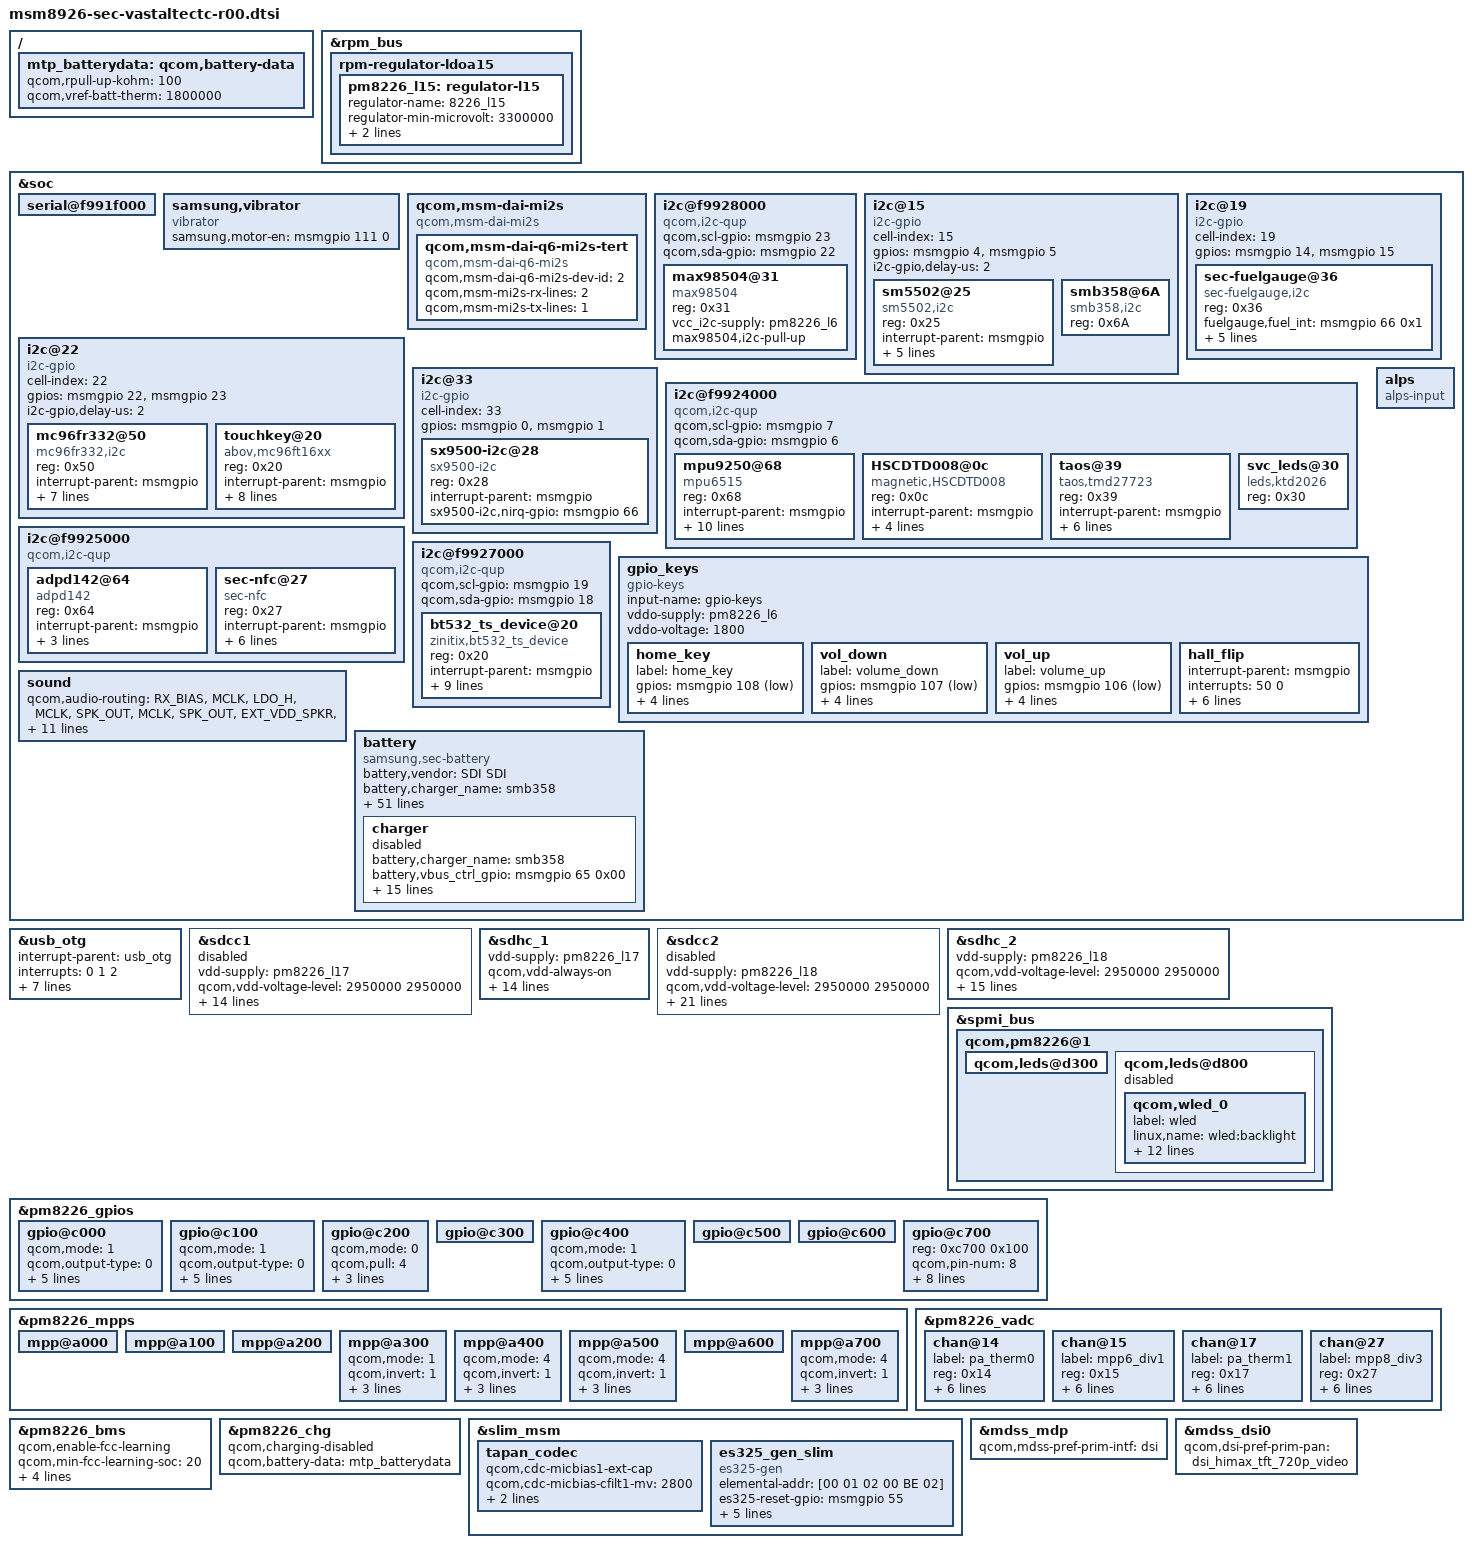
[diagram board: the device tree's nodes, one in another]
/* Copyright (c) 2013, The Linux Foundation. All rights reserved.
 *
 * This program is free software; you can redistribute it and/or modify
 * it under the terms of the GNU General Public License version 2 and
 * only version 2 as published by the Free Software Foundation.
 *
 * This program is distributed in the hope that it will be useful,
 * but WITHOUT ANY WARRANTY; without even the implied warranty of
 * MERCHANTABILITY or FITNESS FOR A PARTICULAR PURPOSE.  See the
 * GNU General Public License for more details.
 */

/include/ "msm8926-camera-sensor-mtp-vastaltectc-r00.dtsi"
/*/include/ "dsi_panel_magna_octa_720p_video_revA.dtsi"*/
/include/ "dsi_panel_himax_hx8394c_tft_720p_video.dtsi"
&rpm_bus {
	rpm-regulator-ldoa15 {
		status = "okay";
		pm8226_l15: regulator-l15 {
			regulator-name = "8226_l15";
			regulator-min-microvolt = <3300000>;
			regulator-max-microvolt = <3300000>;
			qcom,init-voltage = <3300000>;
			status = "okay";
		};
	};
};

&soc {
	serial@f991f000 {
		status = "ok";
	};

	samsung,vibrator{
		compatible = "vibrator";
		samsung,motor-en = <&msmgpio 111 0>;
		status = "ok";
	};

	 /*CONFIG_SND_SOC_MAX98504*/
	qcom,msm-dai-mi2s {
			compatible = "qcom,msm-dai-mi2s";
			qcom,msm-dai-q6-mi2s-tert {
			compatible = "qcom,msm-dai-q6-mi2s";
			qcom,msm-dai-q6-mi2s-dev-id = <2>;
			qcom,msm-mi2s-rx-lines = <2>;
			qcom,msm-mi2s-tx-lines = <1>;
		};
	};

	i2c@f9928000 {	 /*BLSP-1 QUP-6*/
		compatible = "qcom,i2c-qup";
		qcom,scl-gpio = <&msmgpio 23 0>;
		qcom,sda-gpio = <&msmgpio 22 0>;
		max98504@31 {
			compatible = "max98504";
			reg = <0x31>;
			vcc_i2c-supply = <&pm8226_l6>;
			max98504,i2c-pull-up;
		};
	};	/*CONFIG_SND_SOC_MAX98504*/


	i2c@15{ /*SM5502 MUIC Chip node */
		/*Driver file: drivers/misc/sm5502.c*/
		/*CONFIG_SM5502_MUIC*/
                cell-index = <15>;
                compatible = "i2c-gpio";
                gpios = <&msmgpio 4 0  /*SDA*/
                        &msmgpio 5 0  /*SCL*/
                        >;
                i2c-gpio,delay-us = <2>;
                #address-cells = <1>;
                #size-cells = <0>;
                sm5502@25{
                        compatible = "sm5502,i2c";
                        reg = <0x25>;
                        interrupt-parent = <&msmgpio>;
                        interrupts= <52 0>;
                        sm5502,irq-gpio = <&msmgpio 52 0x00>;
                        sm5502,gpio-sda = <&msmgpio 4 0x00>;
                        sm5502,gpio-scl = <&msmgpio 5 0x00>;
                        sm5502,uarton-gpio = <&msmgpio 109 0x00>;
                };
                smb358@6A {
						compatible = "smb358,i2c";
						reg = <0x6A>;
				};
        };

	i2c@19 {
		cell-index = <19>;
		compatible = "i2c-gpio";
		gpios = <&msmgpio 14 0  /* sda */
			&msmgpio 15 0   /* scl */
			>;
		#address-cells = <1>;
		#size-cells = <0>;
		sec-fuelgauge@36 {
			compatible = "sec-fuelgauge,i2c";
			reg = <0x36>;
			fuelgauge,fuel_int = <&msmgpio 66 0x1>;
			fuelgauge,capacity_max = <1000>;
			fuelgauge,capacity_max_margin = <50>;
			fuelgauge,capacity_min = <0>;
			fuelgauge,capacity_calculation_type = <0x17>;
			fuelgauge,fuel_alert_soc = <1>;
			/* fuelgaguge,repeated_fuelalert; */
		};
       };

	i2c@22 { /*MC96FR332/MC96FR116 IRDA Controller IC node*/
		 /*Drvier file: drivers/irda/ir_remote_kmini.c*/
		 /*CONFIG_IR_REMOCON_KMINI*/
		cell-index = <22>;
                compatible = "i2c-gpio";
                gpios = <&msmgpio 22 0 /* sda */
                         &msmgpio 23 0 /* scl */
                         >;
                i2c-gpio,delay-us = <2>;
                #address-cells = <1>;
                #size-cells = <0>;

		mc96fr332@50 {
			compatible = "mc96fr332,i2c";
                        reg = <0x50>;
                        interrupt-parent = <&msmgpio>;
                        vled_3.3v-supply = <&pm8226_l15>;
                        interrupts = <56 0>;
			mc96fr332,irda_irq_gpio = <&msmgpio 56 0x00>;
                        mc96fr332,irda_wake = <&msmgpio 49 0x00>;
			mc96fr332,irda_poweron = <&msmgpio 114 0x00>;
			mc96fr332,scl-gpio = <&msmgpio 23 0x00>;
			mc96fr332,sda-gpio = <&msmgpio 22 0x00>;
		};

		touchkey@20{
			compatible = "abov,mc96ft16xx";
			reg = <0x20>;
			interrupt-parent = <&msmgpio>;
			interrupts = <31 0>;
			abov,sda-gpio = <&msmgpio 22 0>;
			abov,scl-gpio = <&msmgpio 23 0>;
			abov,irq-gpio = <&msmgpio 31 0>;
			abov,rst-gpio = <&msmgpio 38 0>;
			abov,tkey_en-gpio = <&msmgpio 110 0>;
			vddo-supply = <&pm8226_l6>;
			avdd-supply = <&pm8226_l19>;
		};
	};

	i2c@33{
		cell-index = <33>;
		compatible = "i2c-gpio";
		gpios = <&msmgpio 0 0
			&msmgpio 1 0>;
	sx9500-i2c@28 {
			compatible = "sx9500-i2c";
			reg = <0x28>;
			interrupt-parent = <&msmgpio>;
			sx9500-i2c,nirq-gpio = <&msmgpio 66 0x00>;
		};
	};

	i2c@f9924000 { /* BLSP1 QUP2 */
		compatible = "qcom,i2c-qup";
		qcom,scl-gpio = <&msmgpio 7 0>;
		qcom,sda-gpio = <&msmgpio 6 0>;
		status = "okay";
		mpu9250@68 {
			compatible = "mpu6515";
			reg = <0x68>;
			interrupt-parent = <&msmgpio>;
			mpu9250,device_rev = <0>;
			mpu9250,irq_gpio = <&msmgpio 64 0x0>;
			mpu9250,int_config = <0>;
			mpu9250,level_shifter = <0>;
			mpu9250,sec_slave_type = <0>;
			mpu9250,sec_slave_id = <0>;
			mpu9250,orientation = <2 1 1 1 2 1 1 1 2>;
			mpu9250,key = <211 22 205 7
				217 186 151 55
				206 254 35 144
				225 102 47 50>;
			mpu9250-lvs1-supply = <&pm8226_lvs1>;
		};

		HSCDTD008@0c {
			compatible = "magnetic,HSCDTD008";
			reg = <0x0c>;
			interrupt-parent = <&msmgpio>;
			interrupts = <66 0>;
			HSCDTD008-i2c,irq_gpio = <&msmgpio 66 0x1>;
			HSCDTD008-i2c,reg_vdd = "8226_l19";
			HSCDTD008-i2c,reg_vio = "8226_lvs1";
		};

		taos@39 {
			compatible = "taos,tmd27723";
			reg = <0x39>;
			interrupt-parent = <&msmgpio>;
			interrupts = <65 0>;
			taos,irq_gpio = <&msmgpio 65 0>;
			taos,en = <&pm8226_gpios 2 0x00>;
			taos,prox_cal_path = "/efs/prox_cal";
			taos,vdd_2p85 = "8226_l19";
			taos,vdd_1p8 = "8226_lvs1";
		};

		svc_leds@30{
			compatible = "leds,ktd2026";
			reg = <0x30>;
		};
	};
	i2c@f9925000 {
		compatible = "qcom,i2c-qup";
		status = "okay";
		adpd142@64 {
			compatible = "adpd142";
			reg = <0x64>;
			interrupt-parent = <&msmgpio>;
			interrupts = <63 0>;
			adpd142,irq_gpio = <&msmgpio 63 0>;
			adpd142,vdd_1p8 = "8226_l6";
		};
		sec-nfc@27 {
			compatible = "sec-nfc";
			reg = <0x27>;
			interrupt-parent = <&msmgpio>;
			interrupts = <21 0>;
			vdd_nfc-supply = <&pm8226_l6>;
			sec-nfc,firm-gpio = <&msmgpio 62 0x00>;
			sec-nfc,ven-gpio = <&msmgpio 20 0x00>;
			sec-nfc,irq-gpio = <&msmgpio 21 0x01>;
			nfc_ldo-supply = <&pm8226_l22>;
		};
	};

	i2c@f9927000{ /* BLSP1 QUP5 Hardware ID BLSP5 */
		compatible = "qcom,i2c-qup";
		qcom,scl-gpio = <&msmgpio 19 0>;
		qcom,sda-gpio = <&msmgpio 18 0>;
		bt532_ts_device@20 {
				compatible = "zinitix,bt532_ts_device";
				reg = <0x20>;
				interrupt-parent = <&msmgpio>;
				interrupts = <17 0>;
				zinitix,vdd_en-gpio = <&msmgpio 31 0x00>;
				zinitix,irq-gpio = <&msmgpio 17 0x00>;
				zinitix,x_resolution = <720>;
				zinitix,y_resolution = <1280>;
				zinitix,page_size = <128>;
				zinitix,orientation = <0>;
				vddo-supply = <&pm8226_lvs1>;
				zinitix,tsp_vdd_supply_type = <0>;
			};
	};

	gpio_keys {
		compatible = "gpio-keys";
		input-name = "gpio-keys";
		vddo-supply = <&pm8226_l6>;
		vddo-voltage = <1800>;


		home_key {
			label = "home_key";
			gpios = <&msmgpio 108 0x1>;
			linux,input-type = <1>;
			linux,code = <172>;
			gpio-key,wakeup;
			debounce-interval = <15>;
		};

		vol_down {
			label = "volume_down";
			gpios = <&msmgpio 107 0x1>;
			linux,input-type = <1>;
			linux,code = <114>;
			gpio-key,wakeup;
			debounce-interval = <15>;
		};

		vol_up {
			label = "volume_up";
			gpios = <&msmgpio 106 0x1>;
			linux,input-type = <1>;
			linux,code = <115>;
			gpio-key,wakeup;
			debounce-interval = <15>;
		};

		hall_flip {
			interrupt-parent = <&msmgpio>;
			interrupts = <50 0>;

			label = "hall_flip";
			gpios = <&msmgpio 50 0>;
			linux,input-type = <1>;
			linux,code = <0x15>;
			gpio-key,wakeup;
			debounce-interval = <15>;
		};
	};

	alps {
			compatible = "alps-input";
	};

	sound {
		qcom,audio-routing =
			"RX_BIAS", "MCLK",
			"LDO_H", "MCLK",
			"SPK_OUT", "MCLK",
			"SPK_OUT", "EXT_VDD_SPKR",
			"AMIC1", "MIC BIAS1 External",
			"MIC BIAS1 External", "Handset Mic",
			"AMIC2", "MIC BIAS2 External",
			"MIC BIAS2 External", "Headset Mic",
			"AMIC3", "MIC BIAS3 External",
			"MIC BIAS3 External", "Sub Mic",
			"AMIC4", "MIC BIAS2 External",
			"MIC BIAS2 External", "ANCRight Headset Mic",
			"AMIC5", "MIC BIAS2 External",
			"MIC BIAS2 External", "ANCLeft Headset Mic";

		qcom,cdc-mclk-gpios = <&pm8226_gpios 1 0>;
		/*qcom,cdc-vdd-spkr-gpios = <&pm8226_gpios 2 0>;*/
		vdd-earjack-supply = <&pm8226_l19>;
	};

	battery {
		status = "okay";
		compatible = "samsung,sec-battery";
		battery,vendor = "SDI SDI";
		battery,charger_name = "smb358";
		battery,fuelgauge_name = "bms";
		battery,technology = <2>; /* POWER_SUPPLY_TECHNOLOGY_LION */

		battery,chip_vendor = "QCOM";
		battery,temp_adc_type = <1>; /* SEC_BATTERY_ADC_TYPE_AP */

		battery,polling_time = <10 30 30 30 3600>;

		battery,adc_check_count = <5>;

		battery,cable_check_type = <5>; /* SEC_BATTERY_CABLE_CHECK_PSY */
		battery,cable_source_type = <1>; /* SEC_BATTERY_CABLE_SOURCE_EXTERNAL */
		battery,event_check;
		battery,event_waiting_time = <600>;
		battery,polling_type = <1>; /* SEC_BATTERY_MONITOR_ALARM */
		battery,monitor_initial_count = <3>;

		battery,battery_check_type = <0>; /* SEC_BATTERY_CHECK_NONE */
		battery,check_count = <0>;
		battery,check_adc_max = <1440>;
		battery,check_adc_min = <0>;

		battery,ovp_uvlo_check_type = <3>; /* SEC_BATTERY_OVP_UVLO_CHGPOLLING */

		battery,thermal_source = <2>; /* SEC_BATTERY_THERMAL_SOURCE_ADC */

		battery,temp_table_adc = <27281 27669 28178 28724 29342 30101 30912 31807 32823 33858 34950 36049 37054
			38025 38219 38448 38626 38795 38989 39229 39540 39687 39822 40523 41123 41619>;
		battery,temp_table_data = <700 650 600 550 500 450 400 350 300 250 200 150 100
			50 40 30 20 10 0 (-10) (-30) (-40) (-50) (-100) (-150) (-200)>;
		battery,temp_check_type = <2>; /* SEC_BATTERY_TEMP_CHECK_TEMP */
		battery,temp_check_count = <1>;
		battery,temp_high_threshold_event = <600>;
		battery,temp_high_recovery_event = <450>;
		battery,temp_low_threshold_event = <(-50)>;
		battery,temp_low_recovery_event = <0>;
		battery,temp_high_threshold_normal = <600>;
		battery,temp_high_recovery_normal = <450>;
		battery,temp_low_threshold_normal = <(-50)>;
		battery,temp_low_recovery_normal = <0>;
		battery,temp_high_threshold_lpm = <600>;
		battery,temp_high_recovery_lpm = <450>;
		battery,temp_low_threshold_lpm = <(-50)>;
		battery,temp_low_recovery_lpm = <0>;
		battery,full_check_type = <2>; /* SEC_BATTERY_FULLCHARGED_FG_CURRENT */
		battery,full_check_type_2nd = <3>; /* SEC_BATTERY_FULLCHARGED_TIME */
		battery,full_check_count = <1>;
		battery,chg_gpio_full_check = <0>;
		battery,chg_polarity_full_check = <1>;

		/* SEC_BATTERY_FULL_CONDITION_SOC |
		   SEC_BATTERY_FULL_CONDITION_NOTIMEFULL |
		   SEC_BATTERY_FULL_CONDITION_VCELL */
		battery,full_condition_type = <13>;
		battery,full_condition_soc = <97>;
		battery,full_condition_vcell = <4300>;

		battery,recharge_check_count = <1>;
		battery,recharge_condition_type = <4>; /* SEC_BATTERY_RECHARGE_CONDITION_VCELL */
		battery,recharge_condition_soc = <98>;
		battery,recharge_condition_vcell = <4300>;

		battery,charging_total_time = <36000>;
		battery,recharging_total_time = <5400>;
		battery,charging_reset_time = <0>;

		charger{
			status = "disable";
			/* Charger */
			battery,charger_name = "smb358";
			battery,vbus_ctrl_gpio = <&msmgpio 65 0x00>;
			battery,chg_gpio_en = <0>;
			battery,chg_polarity_en = <0>;
			battery,chg_gpio_status = <0>;
			battery,chg_polarity_status = <0>;
			battery,chg_float_voltage = <4340>;
			battery,ovp_uvlo_check_type = <3>; /* SEC_BATTERY_OVP_UVLO_CHGPOLLING */
			battery,full_check_type = <2>; /* SEC_BATTERY_FULLCHARGED_FG_CURRENT */

			battery,input_current_limit = <1000 460 460 1000 460 900 1000 460 460 1000 650 1000 1000 460 1300 300 700 1300 300 1000 1000 460 460>;
			battery,fast_charging_current = <2100 0 460 2100 460 1200 1000 460 0 1200 750 2100 2100 0 1300 300 700 1300 300 1000 2100 0 0>;
			battery,full_check_current_1st = <250 0 250 250 250 250 250 250 0 250 250 250 250 0 250 250 250 250 250 250 250 0 0>;
			battery,full_check_current_2nd = <2400 0 2400 2400 2400 2400 2400 2400 0 2400 2400 2400 2400 0 2400 2400 2400 2400 2400 2400 2400 0 0>;
		};
	};
};

&usb_otg {
	#address-cells = <0>;
	interrupt-parent = <&usb_otg>;
	interrupts = <0 1 2>;
	#interrupt-cells = <1>;
	interrupt-map-mask = <0xffffffff>;
	interrupt-map = <0 &intc 0 134 0
			1 &intc 0 140 0
			2 &spmi_bus 0x0 0x0 0x9 0x0>;
	interrupt-names = "core_irq", "async_irq", "pmic_id_irq";

	qcom,hsusb-otg-mode = <3>;
	vbus_otg-supply = <&pm8226_chg_otg>;
	qcom,hsusb-otg-phy-init-seq =
			<0x44 0x80 0x6F 0x81 0x24 0x82 0x13 0x83 0xffffffff>;
};

&sdcc1 {
	vdd-supply = <&pm8226_l17>;
	qcom,vdd-voltage-level = <2950000 2950000>;
	qcom,vdd-current-level = <800 500000>;

	vdd-io-supply = <&pm8226_l6>;
	qcom,vdd-io-always-on;
	qcom,vdd-io-voltage-level = <1800000 1800000>;
	qcom,vdd-io-current-level = <250 154000>;

	qcom,pad-pull-on = <0x0 0x3 0x3>; /* no-pull, pull-up, pull-up */
	qcom,pad-pull-off = <0x0 0x3 0x3>; /* no-pull, pull-up, pull-up */
	qcom,pad-drv-on = <0x4 0x4 0x4>; /* 10mA, 10mA, 10mA */
	qcom,pad-drv-off = <0x0 0x0 0x0>; /* 2mA, 2mA, 2mA */

	qcom,clk-rates = <400000 25000000 50000000 100000000 200000000>;
	qcom,sup-voltages = <2950 2950>;

	qcom,bus-speed-mode = "HS200_1p8v", "DDR_1p8v";
	qcom,nonremovable;

	status = "disabled";
};

&sdhc_1 {
	vdd-supply = <&pm8226_l17>;
	qcom,vdd-always-on;
	qcom,vdd-voltage-level = <2950000 2950000>;
	qcom,vdd-current-level = <800 500000>;

	vdd-io-supply = <&pm8226_l6>;
	qcom,vdd-io-always-on;
	qcom,vdd-io-voltage-level = <1800000 1800000>;
	qcom,vdd-io-current-level = <250 154000>;

	qcom,pad-pull-on = <0x0 0x3 0x3>; /* no-pull, pull-up, pull-up */
	qcom,pad-pull-off = <0x0 0x3 0x3>; /* no-pull, pull-up, pull-up */
	qcom,pad-drv-on = <0x4 0x4 0x4>; /* 10mA, 10mA, 10mA */
	qcom,pad-drv-off = <0x0 0x0 0x0>; /* 2mA, 2mA, 2mA */

	qcom,clk-rates = <400000 25000000 50000000 100000000 200000000>;
	qcom,bus-speed-mode = "HS200_1p8v", "DDR_1p8v";
	qcom,nonremovable;

	status = "ok";
};

&sdcc2 {
	vdd-supply = <&pm8226_l18>;
	qcom,vdd-voltage-level = <2950000 2950000>;
	qcom,vdd-current-level = <9000 800000>;

	vdd-io-supply = <&pm8226_l21>;
	qcom,vdd-io-voltage-level = <1800000 2950000>;
	qcom,vdd-io-current-level = <6 22000>;

	qcom,pad-pull-on = <0x0 0x3 0x3>; /* no-pull, pull-up, pull-up */
	qcom,pad-pull-off = <0x0 0x3 0x3>; /* no-pull, pull-up, pull-up */
	qcom,pad-drv-on = <0x4 0x4 0x4>; /* 10mA, 10mA, 10mA */
	qcom,pad-drv-off = <0x0 0x0 0x0>; /* 2mA, 2mA, 2mA */

	qcom,clk-rates = <400000 25000000 50000000 100000000 200000000>;
	qcom,sup-voltages = <2950 2950>;

	qcom,xpc;
	qcom,bus-speed-mode = "SDR12", "SDR25", "SDR50", "DDR50", "SDR104";
	qcom,current-limit = <600>; #address-cells = <0>; interrupt-parent = <&sdcc2>;
	interrupts = <0 1 2>;
	#interrupt-cells = <1>;
	interrupt-map-mask = <0xffffffff>;
	interrupt-map = <0 &intc 0 125 0
			1 &intc 0 220 0
			2 &msmgpio 38 0x3>;
	interrupt-names = "core_irq", "bam_irq", "status_irq";
	cd-gpios = <&msmgpio 38 0x1>;

	status = "disabled";
};

&sdhc_2 {
	vdd-supply = <&pm8226_l18>;
	qcom,vdd-voltage-level = <2950000 2950000>;
	qcom,vdd-current-level = <9000 800000>;

	vdd-io-supply = <&pm8226_l21>;
	qcom,vdd-io-voltage-level = <1800000 2950000>;
	qcom,vdd-io-current-level = <6 22000>;

	qcom,pad-pull-on = <0x0 0x3 0x3>; /* no-pull, pull-up, pull-up */
	qcom,pad-pull-off = <0x0 0x3 0x3>; /* no-pull, pull-up, pull-up */
	qcom,pad-drv-on = <0x4 0x4 0x4>; /* 10mA, 10mA, 10mA */
	qcom,pad-drv-off = <0x0 0x0 0x0>; /* 2mA, 2mA, 2mA */

	qcom,clk-rates = <400000 25000000 50000000 100000000 200000000>;

	#address-cells = <0>;
	interrupt-parent = <&sdhc_2>;
	interrupts = <0 1 2>;
	#interrupt-cells = <1>;
	interrupt-map-mask = <0xffffffff>;
	interrupt-map = <0 &intc 0 125 0
			1 &intc 0 221 0
			2 &msmgpio 38 0x3>;
	interrupt-names = "hc_irq", "pwr_irq", "status_irq";

	status = "ok";
};

&spmi_bus {
	qcom,pm8226@1 {
                qcom,leds@d300 {
                        status = "okay";
                };

		qcom,leds@d800 {
			status = "disabled"; /*If WLED is not used for Backlight control*/
			qcom,wled_0 {		/*for TFT Panel, this to be disabled */
				label = "wled";
				linux,name = "wled:backlight";
				linux,default-trigger = "bkl-trigger";
				qcom,cs-out-en;
				qcom,op-fdbck = <1>;
				qcom,default-state = "off";
				qcom,max-current = <20>;
				qcom,ctrl-delay-us = <0>;
				qcom,boost-curr-lim = <3>;
				qcom,cp-sel = <0>;
				qcom,switch-freq = <11>;
				qcom,ovp-val = <0>;
				qcom,num-strings = <1>;
				qcom,id = <0>;
			};
		};
	};
};

&pm8226_gpios {
	gpio@c000 { /* GPIO 1 */
		/* XO_PMIC_CDC_MCLK enable for tapan codec */
		qcom,mode = <1>;		/* Digital output */
		qcom,output-type = <0>;	/* CMOS logic */
		qcom,pull = <5>;		/* QPNP_PIN_PULL_NO*/
		qcom,vin-sel = <3>;		/* QPNP_PIN_VIN3 */
		qcom,out-strength = <3>;/* QPNP_PIN_OUT_STRENGTH_HIGH */
		qcom,src-sel = <2>;		/* QPNP_PIN_SEL_FUNC_1 */
		qcom,master-en = <1>;	/* Enable GPIO */
	};

	gpio@c100 { /* GPIO 2 */
		qcom,mode = <1>;
		qcom,output-type = <0>;
		qcom,pull = <5>;
		qcom,vin-sel = <3>;
		qcom,out-strength = <3>;
		qcom,src-sel = <2>;
		qcom,master-en = <1>;
	};

	gpio@c200 { /* GPIO 3 */
		qcom,mode = <0>;
		qcom,pull = <4>;
		qcom,vin-sel = <2>;
		qcom,src-sel = <0>;
		qcom,master-en = <1>;
	};

	gpio@c300 { /* GPIO 4 */
	};

	gpio@c400 { /* GPIO 5 */
		qcom,mode = <1>;		/* Digital output */
		qcom,output-type = <0>;	/* CMOS logic */
		qcom,pull = <5>;		/* QPNP_PIN_PULL_NO */
		qcom,vin-sel = <3>;		/* QPNP_PIN_VIN2 */
		qcom,out-strength = <3>;/* QPNP_PIN_OUT_STRENGTH_HIGH */
		qcom,src-sel = <2>;		/* QPNP_PIN_SEL_FUNC_1 */
		qcom,master-en = <1>;
	};

	gpio@c500 { /* GPIO 6 */
	};

	gpio@c600 { /* GPIO 7 */
	};

	gpio@c700 { /* GPIO 8 */
		reg = <0xc700 0x100>;
		qcom,pin-num = <8>;
		qcom,mode = <1>;		/* QPNP_PIN_MODE_DIG_OUT */
		qcom,output-type = <0>;		/* QPNP_PIN_OUT_BUF_CMOS */
		qcom,invert = <0>;		/* QPNP_PIN_INVERT_DISABLE */
		qcom,pull = <5>;		/* QPNP_PIN_PULL_NO */
		qcom,vin-sel = <2>;		/* QPNP_PIN_VIN2 = S3 = 1.8V */
		qcom,out-strength = <2>;	/* QPNP_PIN_OUT_STRENGTH_MED */
		qcom,src-sel = <0>;		/* QPNP_PIN_SEL_FUNC_CONSTANT */
		qcom,master-en = <1>;		/* enable this gpio */
	};
};

&pm8226_mpps {
	mpp@a000 { /* MPP 1 */
	};

	mpp@a100 { /* MPP 2 */
	};

	mpp@a200 { /* MPP 3 */
	};

	mpp@a300 { /* MPP 4 */
		qcom,mode = <1>; /*QPNP_PIN_MODE_DIG_OUT */
		qcom,invert = <1>; /* Enable MPP */
		qcom,out-strength = <3>; /*QPNP_PIN_OUT_STRENGTH_HIGH*/
		qcom,master-en = <1>;
		qcom,src-sel = <0>; /* Function constant */
	};

	mpp@a400 { /* MPP 5 */
		/* PA_THERM0 config */
		qcom,mode = <4>; /* AIN input */
		qcom,invert = <1>; /* Enable MPP */
		qcom,ain-route = <0>; /* AMUX 5 */
		qcom,master-en = <1>;
		qcom,src-sel = <0>; /* Function constant */
	};

	mpp@a500 { /* MPP 6 */
		qcom,mode = <4>; /* AIN input */
		qcom,invert = <1>; /* Enable MPP */
		qcom,ain-route = <1>; /* AMUX 6 */
		qcom,master-en = <1>;
		qcom,src-sel = <0>; /* Function constant */
	};

	mpp@a600 { /* MPP 7 */
	};

	mpp@a700 { /* MPP 8 */
		/* PA_THERM1 config */
		qcom,mode = <4>; /* AIN input */
		qcom,invert = <1>; /* Enable MPP */
		qcom,ain-route = <3>; /* AMUX 8 */
		qcom,master-en = <1>;
		qcom,src-sel = <0>; /* Function constant */
	};
};

&pm8226_vadc {
	chan@14 {
		label = "pa_therm0";
		reg = <0x14>;
		qcom,decimation = <0>;
		qcom,pre-div-channel-scaling = <0>;
		qcom,calibration-type = "ratiometric";
		qcom,scale-function = <2>;
		qcom,hw-settle-time = <2>;
		qcom,fast-avg-setup = <0>;
	};

	chan@15 {
		label = "mpp6_div1";
		reg = <0x15>;
		qcom,decimation = <0>;
		qcom,pre-div-channel-scaling = <0>;
		qcom,calibration-type = "absolute";
		qcom,scale-function = <0>;
		qcom,hw-settle-time = <0>;
		qcom,fast-avg-setup = <0>;
	};
	chan@17 {
		label = "pa_therm1";
		reg = <0x17>;
		qcom,decimation = <0>;
		qcom,pre-div-channel-scaling = <0>;
		qcom,calibration-type = "ratiometric";
		qcom,scale-function = <2>;
		qcom,hw-settle-time = <2>;
		qcom,fast-avg-setup = <0>;
	};

	chan@27 {
		label = "mpp8_div3";
		reg = <0x27>;
		qcom,decimation = <0>;
		qcom,pre-div-channel-scaling = <1>;
		qcom,calibration-type = "absolute";
		qcom,scale-function = <0>;
		qcom,hw-settle-time = <0>;
		qcom,fast-avg-setup = <0>;
		};
};

/ {
	mtp_batterydata: qcom,battery-data {
		qcom,rpull-up-kohm = <100>;
		qcom,vref-batt-therm = <1800000>;

		/include/ "batterydata-palladium.dtsi"
		/include/ "batterydata-mtp-3000mah.dtsi"
	};
};

&pm8226_bms {
	status = "ok";
	qcom,enable-fcc-learning;
	qcom,min-fcc-learning-soc = <20>;
	qcom,min-fcc-ocv-pc = <30>;
	qcom,min-fcc-learning-samples = <5>;
	qcom,fcc-resolution = <10>;
	qcom,battery-data = <&mtp_batterydata>;
};

&pm8226_chg {
	qcom,charging-disabled;
	qcom,battery-data = <&mtp_batterydata>;
};

&slim_msm {
	tapan_codec {
		qcom,cdc-micbias1-ext-cap;
		qcom,cdc-micbias-cfilt1-mv = <2800>;
		qcom,cdc-micbias-cfilt2-mv = <2800>;
		qcom,cdc-micbias-cfilt3-mv = <2800>;
	};
	es325_gen_slim {
                compatible = "es325-gen";
                elemental-addr = [00 01 02 00 BE 02];

                es325-reset-gpio = <&msmgpio 55 0>;
                es325-wakeup-gpio = <&msmgpio 53 0>;
                vdd-2mic-core-supply = <&pm8226_l5>;

                es325-slim-ifd = "es325-ifd";
                es325-slim-ifd-elemental-addr = [00 00 02 00 BE 02];
        };

};

&mdss_mdp {
	qcom,mdss-pref-prim-intf = "dsi";
};

&mdss_dsi0 {
	qcom,dsi-pref-prim-pan = <&dsi_himax_tft_720p_video>;
};
